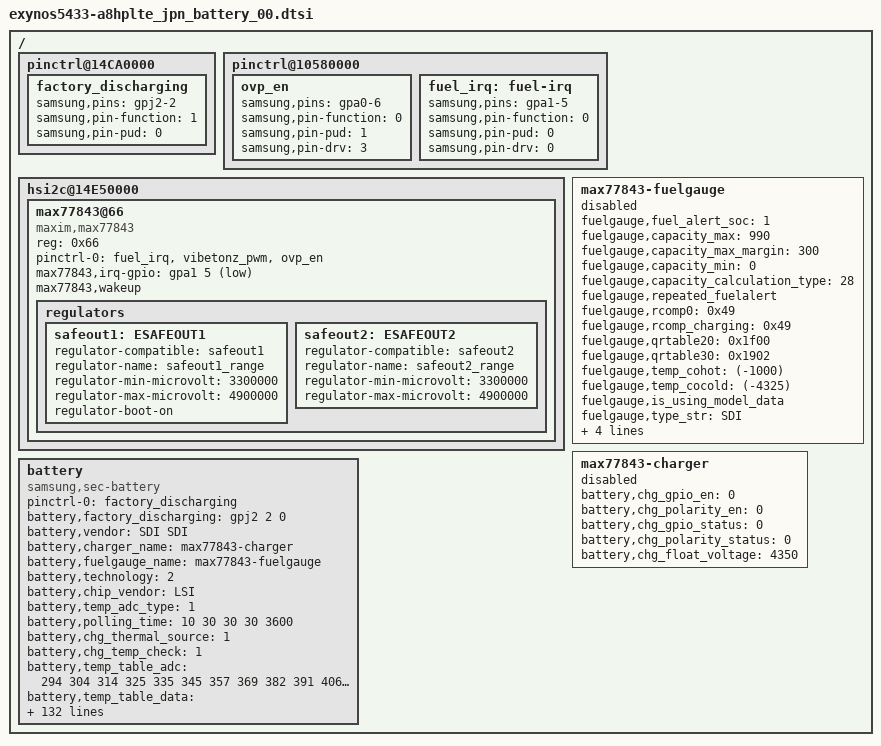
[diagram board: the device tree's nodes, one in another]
/*
 * SAMSUNG UNIVERSAL5433 board device tree source
 *
 * Copyright (c) 2013 Samsung Electronics Co., Ltd.
 *		http://www.samsung.com
 *
 * This program is free software; you can redistribute it and/or modify
 * it under the terms of the GNU General Public License version 2 as
 * published by the Free Software Foundation.
*/

/ {
	pinctrl@14CA0000 {
		factory_discharging: factory_discharging {
			samsung,pins = "gpj2-2";
			samsung,pin-function = <1>;
			samsung,pin-pud = <0>;
		};
	};

	pinctrl@10580000 {
		ovp_en: ovp_en {
			samsung,pins = "gpa0-6";
			samsung,pin-function = <0>;
			samsung,pin-pud = <1>;
			samsung,pin-drv = <3>;
		};
	};

	pinctrl@10580000 {
		fuel_irq: fuel-irq {
			samsung,pins = "gpa1-5";
			samsung,pin-function = <0>;
			samsung,pin-pud = <0>;
			samsung,pin-drv = <0>;
		};
	};

	hsi2c@14E50000 {
		status = "okay";
		max77843@66 {
			status = "okay";
			compatible = "maxim,max77843";
			reg = <0x66>;
			pinctrl-names = "default";
			pinctrl-0 = <&fuel_irq &vibetonz_pwm &ovp_en>;
			max77843,irq-gpio = <&gpa1 5 1>;
			max77843,wakeup;

			regulators {
				safeout1: ESAFEOUT1 {
					regulator-compatible = "safeout1";
					regulator-name = "safeout1_range";
					regulator-min-microvolt = <3300000>;
					regulator-max-microvolt = <4900000>;
					regulator-boot-on;
				};

				safeout2: ESAFEOUT2 {
					regulator-compatible = "safeout2";
					regulator-name = "safeout2_range";
					regulator-min-microvolt = <3300000>;
					regulator-max-microvolt = <4900000>;
				};
			};
		};
	};
	battery {
		status = "okay";

		pinctrl-names = "default";
		pinctrl-0 = <&factory_discharging>;

		battery,factory_discharging = <&gpj2 2 0>;

		compatible = "samsung,sec-battery";
		battery,vendor = "SDI SDI";
		battery,charger_name = "max77843-charger";
		battery,fuelgauge_name = "max77843-fuelgauge";
		battery,technology = <2>; /* POWER_SUPPLY_TECHNOLOGY_LION */
		/* .temp_cohot = -1000; */
		/* .temp_cocold = -4325; */

		battery,chip_vendor = "LSI";
		battery,temp_adc_type = <1>; /* SEC_BATTERY_ADC_TYPE_AP */

		battery,polling_time = <10 30 30 30 3600>;
		battery,chg_thermal_source = <1>; /* SEC_CHARGER_THERMAL_SOURCE_ADC */
		battery,chg_temp_check = <1>;

		battery,temp_table_adc = <294 304 314 325 335 345 357 369 382 391
				  406 420 434 449 463 477 494 511 527 544
			554 573 591 610 628 646 670 693 717 740
			763 788 813 838 863 888 918 948 977 1007
			1036 1070 1103 1137 1170 1203 1241 1279 1316 1354
			1391 1432 1473 1514 1555 1595 1640 1684 1729 1773
			1817 1865 1912 1959 2006 2053 2098 2142 2186 2230
			2274 2327 2379 2432 2484 2536 2582 2628 2673 2719
			2764 2808 2851 2895 2938 2981 3024 3066 3109 3151
			3193 3229 3264 3300 3335 3370 3401 3432 3463 3494
			3524 3550 3576 3601 3627 3652 3673 3693 3714 3734 3754>;

		battery,temp_table_data = <900 890 880 870 860 850 840 830 820 810
			800 790 780 770 760 750 740 730 720 710
			700 690 680 670 660 650 640 630 620 610
			600 590 580 570 560 550 540 530 520 510
			500 490 480 470 460 450 440 430 420 410
			400 390 380 370 360 350 340 330 320 310
			300 290 280 270 260 250 240 230 220 210
			200 190 180 170 160 150 140 130 120 110
			100 90 80 70 60 50 40 30 20 10
			0 (-10) (-20) (-30) (-40) (-50) (-60) (-70) (-80) (-90)
			(-100) (-110) (-120) (-130) (-140) (-150) (-160) (-170) (-180) (-190) (-200)>;

		battery,chg_temp_table_adc = <294 304 314 325 335 345 357 369 382 391
				  406 420 434 449 463 477 494 511 527 544
			554 573 591 610 628 646 670 693 717 740
			763 788 813 838 863 888 918 948 977 1007
			1036 1070 1103 1137 1170 1203 1241 1279 1316 1354
			1391 1432 1473 1514 1555 1595 1640 1684 1729 1773
			1817 1865 1912 1959 2006 2053 2098 2142 2186 2230
			2274 2327 2379 2432 2484 2536 2582 2628 2673 2719
			2764 2808 2851 2895 2938 2981 3024 3066 3109 3151
			3193 3229 3264 3300 3335 3370 3401 3432 3463 3494
			3524 3550 3576 3601 3627 3652 3673 3693 3714 3734 3754>;

		battery,chg_temp_table_data = <900 890 880 870 860 850 840 830 820 810
			800 790 780 770 760 750 740 730 720 710
			700 690 680 670 660 650 640 630 620 610
			600 590 580 570 560 550 540 530 520 510
			500 490 480 470 460 450 440 430 420 410
			400 390 380 370 360 350 340 330 320 310
			300 290 280 270 260 250 240 230 220 210
			200 190 180 170 160 150 140 130 120 110
			100 90 80 70 60 50 40 30 20 10
			0 (-10) (-20) (-30) (-40) (-50) (-60) (-70) (-80) (-90)
			(-100) (-110) (-120) (-130) (-140) (-150) (-160) (-170) (-180) (-190) (-200)>;

		battery,inbat_voltage = <1>;
		battery,inbat_voltage_table_adc = <2800 2789 2768 2737 2704 2678 2646 2619 2590 2556
						2516 2499 2460 2440 2413 2381 2352 2310 2290 2267 2233>;
		battery,inbat_voltage_table_data = <438 435 430 425 420 415 410 405 400 395
						390 385 380 375 370 365 360 355 350 345 340>;

		battery,input_current_limit = <1800 460 460 1800 500 900 1800 460 1000 460 900 900 900 1900 1800 460 460 400 700 1300 300 1000 1800 460 1667 2100 1000 1667 80 1800 1667 1400 1000 1000 700 900 900 900 500 1800 1667 3000>;
		battery,fast_charging_current = <2000 460 460 2000 800 1200 1500 460 1200 460 2000 2000 2000 1600 2000 460 460 400 700 1300 300 1000 1500 460 2300 2300 500 2300 80 1800 1000 1400 460 1000 2000 2000 2000 2000 460 2300 2300 2300>;
		battery,full_check_current_1st = <300 0 0 300 300 300 300 300 300 0 300 300 300 300 300 0 0 300 300 300 300 300 300 0 300 300 300 300 0 300 300 300 0 300 300 300 300 300 300 300 300 300>;
		battery,full_check_current_2nd = <150 0 0 150 150 150 150 150 150 0 150 150 150 150 150 0 0 150 150 150 150 150 150 0 150 150 150 150 0 150 150 150 0 150 150 150 150 150 150 150 150 150>;

		battery,adc_check_count = <5>;

		battery,cable_check_type = <4>; /* SEC_BATTERY_CABLE_CHECK_PSY */
		battery,cable_source_type = <1>; /* SEC_BATTERY_CABLE_SOURCE_EXTERNAL */
		battery,event_waiting_time = <600>;
		battery,polling_type = <1>; /* SEC_BATTERY_MONITOR_ALARM */
		battery,monitor_initial_count = <0>;
		battery,pre_afc_input_current = <500>;
		
		battery,factory_fast_charging_current = <1000>;

		battery,battery_check_type = <0>; /* SEC_BATTERY_CHECK_NONE */
		battery,check_count = <0>;
		battery,check_adc_max = <1440>;
		battery,check_adc_min = <0>;

		battery,ovp_uvlo_check_type = <3>; /* SEC_BATTERY_OVP_UVLO_CHGPOLLING */

		battery,thermal_source = <2>; /* SEC_BATTERY_THERMAL_SOURCE_ADC */

		battery,temp_check_type = <2>; /* SEC_BATTERY_TEMP_CHECK_TEMP */
		battery,temp_check_count = <1>;
		battery,temp_highlimit_threshold_event = <800>;
		battery,temp_highlimit_recovery_event = <750>;
		battery,temp_high_threshold_event = <500>;
		battery,temp_high_recovery_event = <450>;
		battery,temp_low_threshold_event = <(0)>;
		battery,temp_low_recovery_event = <5>;
		battery,temp_highlimit_threshold_normal = <800>;
		battery,temp_highlimit_recovery_normal = <750>;
		battery,temp_high_threshold_normal = <500>;
		battery,temp_high_recovery_normal = <450>;
		battery,temp_low_threshold_normal = <0>;
		battery,temp_low_recovery_normal = <50>;
		battery,temp_highlimit_threshold_lpm = <800>;
		battery,temp_highlimit_recovery_lpm = <750>;
		battery,temp_high_threshold_lpm = <500>;
		battery,temp_high_recovery_lpm = <450>;
		battery,temp_low_threshold_lpm = <0>;
		battery,temp_low_recovery_lpm = <50>;
		battery,full_check_type = <7>; /* SEC_BATTERY_FULLCHARGED_CHGPSY */
		battery,full_check_type_2nd = <7>; /* SEC_BATTERY_FULLCHARGED_CHGPSY */
		battery,full_check_count = <1>;
		battery,chg_gpio_full_check = <0>;
		battery,chg_polarity_full_check = <1>;

		battery,chg_heating_prevention_method = <0>; /* SEC_BATTERY_BY_CHANGING_VOLTAGE */
		battery,chg_12v_high_temp = <615>;
		battery,chg_high_temp = <465>;
		battery,chg_high_temp_recovery = <460>;
		battery,chg_charging_limit_current = <1100>;

		battery,wpc_high_temp = <460 495>;
		battery,wpc_high_temp_recovery = <459 400>;
		battery,wpc_charging_limit_current = <540 400>;
		battery,wpc_heat_temp_recovery = <360>;
		battery,wpc_lcd_on_high_temp = <470>;
		battery,wpc_lcd_on_high_temp_rec = <300>;
		battery,wpc_hv_lcd_on_input_limit_current = <400>;

		battery,sleep_mode_limit_current = <500>;
		battery,wc_full_input_limit_current = <100>;
		battery,wc_heating_input_limit_current = <400>;
		battery,wc_heating_time = <300>; /* 5 min */
		battery,wc_cv_current = <820>;
		battery,wc_cv_pack_current = <630>;

		battery,mix_high_temp = <420>;
		battery,mix_high_chg_temp = <500>;
		battery,mix_high_temp_recovery = <390>;
		/* SEC_BATTERY_FULL_CONDITION_SOC |
		   SEC_BATTERY_FULL_CONDITION_NOTIMEFULL |
		   SEC_BATTERY_FULL_CONDITION_VCELL */
		battery,full_condition_type = <13>;
		battery,full_condition_soc = <93>;
		battery,full_condition_vcell = <4250>;

		battery,recharge_check_count = <2>;
		battery,recharge_condition_type = <4>; /* SEC_BATTERY_RECHARGE_CONDITION_VCELL */
		battery,recharge_condition_soc = <98>;
		battery,recharge_condition_vcell = <4280>;
		
		battery,expired_time = <11400>;
		battery,recharginig_expired_time = <5400>;
		battery,standard_curr = <2160>;

		battery,charging_total_time = <21600>;
		battery,recharging_total_time = <5400>;
		battery,charging_reset_time = <0>;

		io-channels = <&exynos_adc 1>, <&exynos_adc 7>, <&exynos_adc 3>, <&exynos_adc 4>;
		io-channel-names = "adc-temp", "adc-in-bat", "discharging-check-adc", "adc-chg-temp";
		#io-channel-cells = <4>;
		io-channel-ranges;

		battery,chg_float_voltage = <4350>;
		battery,swelling_high_temp_block = <410>;
		battery,swelling_high_temp_recov = <390>;

		battery,swelling_low_temp_2step_mode = <1>;
		battery,swelling_low_temp_block_1st = <150>;
		battery,swelling_low_temp_recov_1st = <200>;
		battery,swelling_low_temp_block_2nd = <50>;
		battery,swelling_low_temp_recov_2nd = <100>;

		battery,swelling_low_temp_current = <720>;
		battery,swelling_low_temp_topoff = <150>;
		battery,swelling_high_temp_current = <1080>;
		battery,swelling_high_temp_topoff = <150>;
		battery,swelling_drop_float_voltage = <4150>;
		battery,swelling_high_rechg_voltage = <4000>;
		battery,swelling_low_rechg_voltage = <4000>;

		battery,siop_event_check_type = <1>;
		battery,siop_call_cv_current = <330>;
		battery,siop_call_cc_current = <330>;
		battery,siop_input_limit_current = <1200>;
		battery,siop_charging_limit_current = <1000>;
		battery,siop_hv_input_limit_current = <700>;
		battery,siop_hv_charging_limit_current = <1000>;
		battery,siop_hv_12v_input_limit_current = <535>;
		battery,siop_hv_12v_charging_limit_current = <1000>;

		battery,siop_wireless_input_limit_current = <600>;
		battery,siop_wireless_charging_limit_current = <1000>;
		battery,siop_hv_wireless_input_limit_current = <600>;
		battery,siop_hv_wireless_charging_limit_current = <1000>;

                battery,ttf_hv_12v_charge_current = <2350>;
		battery,ttf_hv_charge_current = <2200>;
		battery,ttf_hv_wireless_charge_current = <1500>;

		battery,prepare_afc_delay = <0>;

		/* cycle, chg_float_voltage, recharge_condition_vcell, full_condition_vcell, full_condition_soc */
		battery,age_data = <0 4350 4280 4250 93	/*4.35*/
				200 4330 4260 4230 91	/*4.33*/
				250 4310 4240 4210 89	/*4.31*/
				300 4290 4220 4190 87	/*4.29*/
				1000 4240 4170 4140 83	/*4.24*/
				>;
	};

	max77843-fuelgauge {
		status = "disable";
		fuelgauge,fuel_alert_soc = <1>;
		fuelgauge,capacity_max = <990>;
		fuelgauge,capacity_max_margin = <300>;
		fuelgauge,capacity_min = <0>;
		fuelgauge,capacity_calculation_type = <28>;
		fuelgauge,repeated_fuelalert;
		fuelgauge,rcomp0 = <0x49>;
		fuelgauge,rcomp_charging = <0x49>;
		fuelgauge,qrtable20 = <0x1f00>;
		fuelgauge,qrtable30 = <0x1902>;
		fuelgauge,temp_cohot = <(-1000)>;
		fuelgauge,temp_cocold = <(-4325)>;
		fuelgauge,is_using_model_data;
		fuelgauge,type_str = "SDI";
		fuelgauge,capacity = <0x162a>;
		fuelgauge,low_battery_comp_voltage = <3600>;
		fuelgauge,low_battery_table = <(-5000) 0 0 (-1250) 0 3320 (-750) 97 3451 (-100) 96 3461 0 0 3456>;

	};
	max77843-charger {
	        status = "disable";
		battery,chg_gpio_en = <0>;
		battery,chg_polarity_en = <0>;
		battery,chg_gpio_status = <0>;
		battery,chg_polarity_status = <0>;
		battery,chg_float_voltage = <4350>;
	};
};
